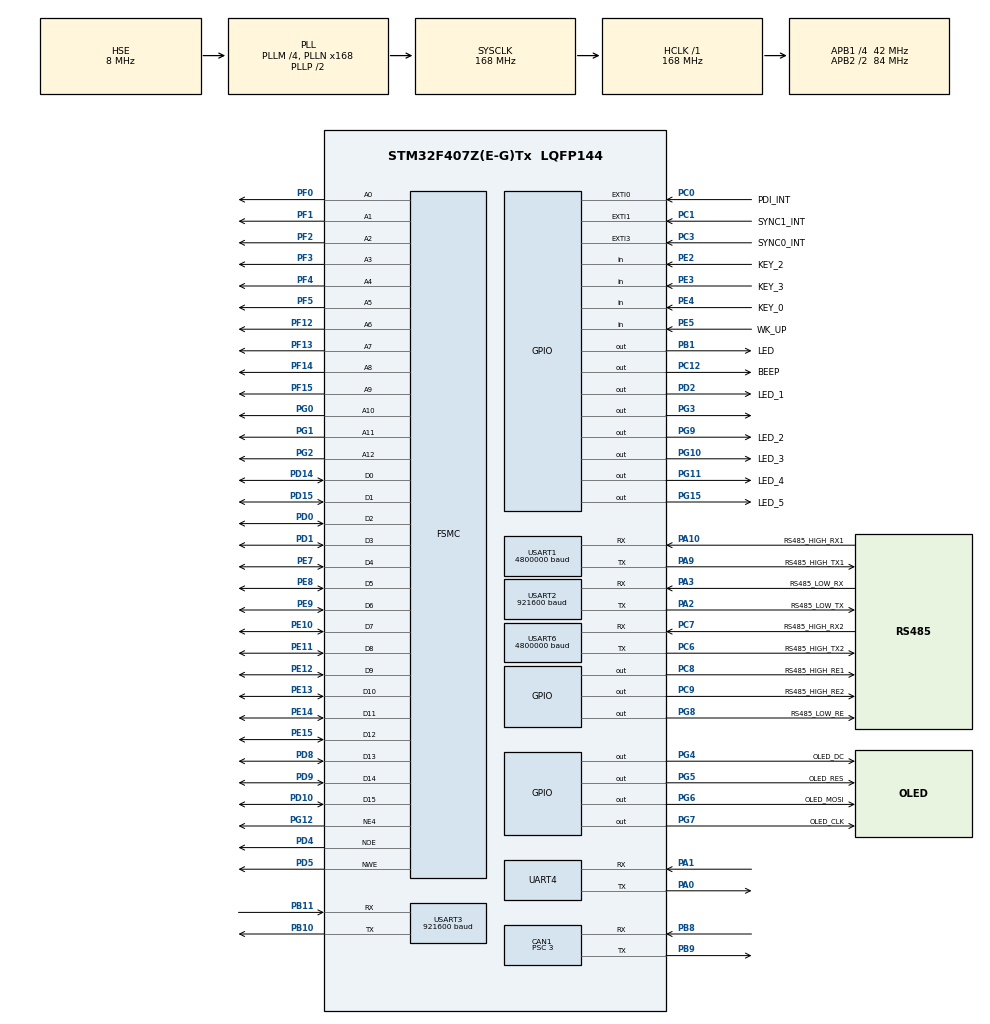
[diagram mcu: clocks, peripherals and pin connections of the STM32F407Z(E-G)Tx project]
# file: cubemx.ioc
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CAN1.BS1=CAN_BS1_9TQ
CAN1.BS2=CAN_BS2_4TQ
CAN1.CalculateBaudRate=1000000
CAN1.CalculateTimeBit=1000
CAN1.CalculateTimeQuantum=71.42857142857143
CAN1.Prescaler=3
Dma.Request0=USART1_RX
Dma.Request1=USART6_RX
Dma.Request2=USART1_TX
Dma.Request3=USART6_TX
Dma.USART1_RX.0.Direction=DMA_PERIPH_TO_MEMORY
Dma.USART1_RX.0.FIFOMode=DMA_FIFOMODE_DISABLE
Dma.USART1_RX.0.Instance=DMA2_Stream5
Dma.USART1_RX.0.MemDataAlignment=DMA_MDATAALIGN_BYTE
Dma.USART1_RX.0.MemInc=DMA_MINC_ENABLE
Dma.USART1_RX.0.Mode=DMA_NORMAL
Dma.USART1_RX.0.PeriphDataAlignment=DMA_PDATAALIGN_BYTE
Dma.USART1_RX.0.PeriphInc=DMA_PINC_DISABLE
Dma.USART1_RX.0.Priority=DMA_PRIORITY_VERY_HIGH
Dma.USART1_TX.2.Direction=DMA_MEMORY_TO_PERIPH
Dma.USART1_TX.2.FIFOMode=DMA_FIFOMODE_DISABLE
Dma.USART1_TX.2.Instance=DMA2_Stream7
Dma.USART1_TX.2.MemDataAlignment=DMA_MDATAALIGN_BYTE
Dma.USART1_TX.2.MemInc=DMA_MINC_ENABLE
Dma.USART1_TX.2.Mode=DMA_NORMAL
Dma.USART1_TX.2.PeriphDataAlignment=DMA_PDATAALIGN_BYTE
Dma.USART1_TX.2.PeriphInc=DMA_PINC_DISABLE
Dma.USART1_TX.2.Priority=DMA_PRIORITY_VERY_HIGH
Dma.USART6_RX.1.Direction=DMA_PERIPH_TO_MEMORY
Dma.USART6_RX.1.FIFOMode=DMA_FIFOMODE_DISABLE
Dma.USART6_RX.1.Instance=DMA2_Stream2
Dma.USART6_RX.1.MemDataAlignment=DMA_MDATAALIGN_BYTE
Dma.USART6_RX.1.MemInc=DMA_MINC_ENABLE
Dma.USART6_RX.1.Mode=DMA_NORMAL
Dma.USART6_RX.1.PeriphDataAlignment=DMA_PDATAALIGN_BYTE
Dma.USART6_RX.1.PeriphInc=DMA_PINC_DISABLE
Dma.USART6_RX.1.Priority=DMA_PRIORITY_VERY_HIGH
Dma.USART6_TX.3.Direction=DMA_MEMORY_TO_PERIPH
Dma.USART6_TX.3.FIFOMode=DMA_FIFOMODE_DISABLE
Dma.USART6_TX.3.Instance=DMA2_Stream6
Dma.USART6_TX.3.MemDataAlignment=DMA_MDATAALIGN_BYTE
Dma.USART6_TX.3.MemInc=DMA_MINC_ENABLE
Dma.USART6_TX.3.Mode=DMA_NORMAL
Dma.USART6_TX.3.PeriphDataAlignment=DMA_PDATAALIGN_BYTE
Dma.USART6_TX.3.PeriphInc=DMA_PINC_DISABLE
Dma.USART6_TX.3.Priority=DMA_PRIORITY_VERY_HIGH
FSMC.AddressSetupTime1=1
FSMC.BusTurnAroundDuration1=2
FSMC.DataSetupTime1=95
FSMC.WriteOperation1=FSMC_WRITE_OPERATION_ENABLE
Mcu.Family=STM32F4
Mcu.Name=STM32F407Z(E-G)Tx
Mcu.Package=LQFP144
NVIC.CAN1_RX0_IRQn=true\:0\:0\:false\:false\:true\:true\:true\:true
NVIC.CAN1_RX1_IRQn=true\:0\:0\:false\:false\:true\:true\:true\:true
NVIC.DMA2_Stream2_IRQn=true\:0\:0\:false\:false\:true\:true\:true\:true
NVIC.DMA2_Stream5_IRQn=true\:0\:0\:false\:false\:true\:false\:true\:true
NVIC.DMA2_Stream6_IRQn=true\:0\:0\:false\:false\:true\:false\:true\:true
NVIC.DMA2_Stream7_IRQn=true\:0\:0\:false\:false\:true\:false\:true\:true
NVIC.EXTI0_IRQn=true\:0\:0\:false\:false\:true\:true\:true\:true
NVIC.EXTI1_IRQn=true\:0\:0\:false\:false\:true\:true\:true\:true
NVIC.EXTI3_IRQn=true\:0\:0\:false\:false\:true\:true\:true\:true
NVIC.PriorityGroup=NVIC_PRIORITYGROUP_4
NVIC.TIM2_IRQn=true\:0\:0\:true\:false\:true\:true\:true\:true
NVIC.TIM3_IRQn=true\:5\:0\:true\:false\:true\:true\:true\:true
NVIC.TIM4_IRQn=true\:1\:0\:true\:false\:true\:true\:true\:true
NVIC.TIM5_IRQn=true\:0\:0\:true\:false\:true\:true\:true\:true
NVIC.UART4_IRQn=true\:0\:0\:false\:false\:true\:true\:true\:true
NVIC.USART1_IRQn=true\:0\:0\:false\:false\:true\:true\:true\:true
NVIC.USART2_IRQn=true\:0\:0\:false\:false\:true\:true\:true\:true
NVIC.USART3_IRQn=true\:0\:0\:false\:false\:true\:true\:true\:true
NVIC.USART6_IRQn=true\:0\:0\:false\:false\:true\:true\:true\:true
PA0-WKUP.Mode=Asynchronous
PA0-WKUP.Signal=UART4_TX
PA1.Mode=Asynchronous
PA1.Signal=UART4_RX
PA10.GPIO_Label=RS485_HIGH_RX1
PA10.Mode=Asynchronous
PA10.Signal=USART1_RX
PA13.Mode=Serial_Wire
PA13.Signal=SYS_JTMS-SWDIO
PA14.Mode=Serial_Wire
PA14.Signal=SYS_JTCK-SWCLK
PA2.GPIO_Label=RS485_LOW_TX
PA2.Mode=Asynchronous
PA2.Signal=USART2_TX
PA3.GPIO_Label=RS485_LOW_RX
PA3.Mode=Asynchronous
PA3.Signal=USART2_RX
PA9.GPIO_Label=RS485_HIGH_TX1
PA9.Mode=Asynchronous
PA9.Signal=USART1_TX
PB1.GPIO_Label=LED
PB1.Signal=GPIO_Output
PB10.Mode=Asynchronous
PB10.Signal=USART3_TX
PB11.Mode=Asynchronous
PB11.Signal=USART3_RX
PB8.Mode=CAN_Activate
PB8.Signal=CAN1_RX
PB9.Mode=CAN_Activate
PB9.Signal=CAN1_TX
PC0.GPIO_Label=PDI_INT
PC0.GPIO_ModeDefaultEXTI=GPIO_MODE_IT_FALLING
PC0.GPIO_PuPd=GPIO_PULLUP
PC0.Signal=GPXTI0
PC1.GPIO_Label=SYNC1_INT
PC1.GPIO_ModeDefaultEXTI=GPIO_MODE_IT_FALLING
PC1.GPIO_PuPd=GPIO_PULLUP
PC1.Signal=GPXTI1
PC12.GPIO_Label=BEEP
PC12.GPIO_PuPd=GPIO_PULLDOWN
PC12.GPIO_Speed=GPIO_SPEED_FREQ_HIGH
PC12.Signal=GPIO_Output
PC3.GPIO_Label=SYNC0_INT
PC3.GPIO_ModeDefaultEXTI=GPIO_MODE_IT_FALLING
PC3.GPIO_PuPd=GPIO_PULLUP
PC3.Signal=GPXTI3
PC6.GPIO_Label=RS485_HIGH_TX2
PC6.Mode=Asynchronous
PC6.Signal=USART6_TX
PC7.GPIO_Label=RS485_HIGH_RX2
PC7.Mode=Asynchronous
PC7.Signal=USART6_RX
PC8.GPIO_Label=RS485_HIGH_RE1
PC8.GPIO_PuPd=GPIO_PULLUP
PC8.GPIO_Speed=GPIO_SPEED_FREQ_HIGH
PC8.Signal=GPIO_Output
PC9.GPIO_Label=RS485_HIGH_RE2
PC9.GPIO_PuPd=GPIO_PULLUP
PC9.GPIO_Speed=GPIO_SPEED_FREQ_HIGH
PC9.Signal=GPIO_Output
PD0.Signal=FSMC_D2_DA2
PD1.Signal=FSMC_D3_DA3
PD10.Signal=FSMC_D15_DA15
PD14.Signal=FSMC_D0_DA0
PD15.Signal=FSMC_D1_DA1
PD2.GPIO_Label=LED_1
PD2.Signal=GPIO_Output
PD4.Signal=FSMC_NOE
PD5.Signal=FSMC_NWE
PD8.Signal=FSMC_D13_DA13
PD9.Signal=FSMC_D14_DA14
PE10.Signal=FSMC_D7_DA7
PE11.Signal=FSMC_D8_DA8
PE12.Signal=FSMC_D9_DA9
PE13.Signal=FSMC_D10_DA10
PE14.Signal=FSMC_D11_DA11
PE15.Signal=FSMC_D12_DA12
PE2.GPIO_Label=KEY_2
PE2.GPIO_PuPd=GPIO_PULLUP
PE2.Signal=GPIO_Input
PE3.GPIO_Label=KEY_3
PE3.GPIO_PuPd=GPIO_PULLUP
PE3.Signal=GPIO_Input
PE4.GPIO_Label=KEY_0
PE4.GPIO_PuPd=GPIO_PULLUP
PE4.Signal=GPIO_Input
PE5.GPIO_Label=WK_UP
PE5.GPIO_PuPd=GPIO_PULLUP
PE5.Signal=GPIO_Input
PE7.Signal=FSMC_D4_DA4
PE8.Signal=FSMC_D5_DA5
PE9.Signal=FSMC_D6_DA6
PF0.Signal=FSMC_A0
PF1.Signal=FSMC_A1
PF12.Signal=FSMC_A6
PF13.Signal=FSMC_A7
PF14.Signal=FSMC_A8
PF15.Signal=FSMC_A9
PF2.Signal=FSMC_A2
PF3.Signal=FSMC_A3
PF4.Signal=FSMC_A4
PF5.Signal=FSMC_A5
PG0.Signal=FSMC_A10
PG1.Signal=FSMC_A11
PG10.GPIO_Label=LED_3
PG10.Signal=GPIO_Output
PG11.GPIO_Label=LED_4
PG11.Signal=GPIO_Output
PG12.Mode=NorPsramChipSelect4_1
PG12.Signal=FSMC_NE4
PG15.GPIO_Label=LED_5
PG15.Signal=GPIO_Output
PG2.Signal=FSMC_A12
PG3.Signal=GPIO_Output
PG4.GPIO_Label=OLED_DC
PG4.GPIO_PuPd=GPIO_PULLUP
PG4.GPIO_Speed=GPIO_SPEED_FREQ_HIGH
PG4.Signal=GPIO_Output
PG5.GPIO_Label=OLED_RES
PG5.GPIO_PuPd=GPIO_PULLUP
PG5.GPIO_Speed=GPIO_SPEED_FREQ_HIGH
PG5.Signal=GPIO_Output
PG6.GPIO_Label=OLED_MOSI
PG6.GPIO_PuPd=GPIO_PULLUP
PG6.GPIO_Speed=GPIO_SPEED_FREQ_HIGH
PG6.Signal=GPIO_Output
PG7.GPIO_Label=OLED_CLK
PG7.GPIO_PuPd=GPIO_PULLUP
PG7.GPIO_Speed=GPIO_SPEED_FREQ_HIGH
PG7.Signal=GPIO_Output
PG8.GPIO_Label=RS485_LOW_RE
PG8.GPIO_PuPd=GPIO_PULLUP
PG8.GPIO_Speed=GPIO_SPEED_FREQ_HIGH
PG8.Signal=GPIO_Output
PG9.GPIO_Label=LED_2
PG9.GPIO_ModeDefaultOutputPP=GPIO_MODE_OUTPUT_PP
PG9.Signal=GPIO_Output
PH0-OSC_IN.Mode=HSE-External-Oscillator
PH0-OSC_IN.Signal=RCC_OSC_IN
PH1-OSC_OUT.Mode=HSE-External-Oscillator
PH1-OSC_OUT.Signal=RCC_OSC_OUT
ProjectManager.HeapSize=0x2000
ProjectManager.StackSize=0x4000
ProjectManager.TargetToolchain=MDK-ARM V5.32
RCC.48MHZClocksFreq_Value=84000000
RCC.AHBFreq_Value=168000000
RCC.APB1CLKDivider=RCC_HCLK_DIV4
RCC.APB1Freq_Value=42000000
RCC.APB1TimFreq_Value=84000000
RCC.APB2CLKDivider=RCC_HCLK_DIV2
RCC.APB2Freq_Value=84000000
RCC.APB2TimFreq_Value=168000000
RCC.CortexFreq_Value=168000000
RCC.HCLKFreq_Value=168000000
RCC.HSE_VALUE=8000000
RCC.HSI_VALUE=16000000
RCC.LSE_VALUE=32768
RCC.PLLM=4
RCC.PLLN=168
RCC.PLLSourceVirtual=RCC_PLLSOURCE_HSE
RCC.SYSCLKFreq_VALUE=168000000
RCC.SYSCLKSource=RCC_SYSCLKSOURCE_PLLCLK
RCC.VCOOutputFreq_Value=336000000
SH.FSMC_A0.0=FSMC_A0,13b-a1
SH.FSMC_A1.0=FSMC_A1,13b-a1
SH.FSMC_A10.0=FSMC_A10,13b-a1
SH.FSMC_A11.0=FSMC_A11,13b-a1
SH.FSMC_A12.0=FSMC_A12,13b-a1
SH.FSMC_A2.0=FSMC_A2,13b-a1
SH.FSMC_A3.0=FSMC_A3,13b-a1
SH.FSMC_A4.0=FSMC_A4,13b-a1
SH.FSMC_A5.0=FSMC_A5,13b-a1
SH.FSMC_A6.0=FSMC_A6,13b-a1
SH.FSMC_A7.0=FSMC_A7,13b-a1
SH.FSMC_A8.0=FSMC_A8,13b-a1
SH.FSMC_A9.0=FSMC_A9,13b-a1
SH.FSMC_D0_DA0.0=FSMC_D0,16b-d1
SH.FSMC_D10_DA10.0=FSMC_D10,16b-d1
SH.FSMC_D11_DA11.0=FSMC_D11,16b-d1
SH.FSMC_D12_DA12.0=FSMC_D12,16b-d1
SH.FSMC_D13_DA13.0=FSMC_D13,16b-d1
SH.FSMC_D14_DA14.0=FSMC_D14,16b-d1
SH.FSMC_D15_DA15.0=FSMC_D15,16b-d1
SH.FSMC_D1_DA1.0=FSMC_D1,16b-d1
SH.FSMC_D2_DA2.0=FSMC_D2,16b-d1
SH.FSMC_D3_DA3.0=FSMC_D3,16b-d1
SH.FSMC_D4_DA4.0=FSMC_D4,16b-d1
SH.FSMC_D5_DA5.0=FSMC_D5,16b-d1
SH.FSMC_D6_DA6.0=FSMC_D6,16b-d1
SH.FSMC_D7_DA7.0=FSMC_D7,16b-d1
SH.FSMC_D8_DA8.0=FSMC_D8,16b-d1
SH.FSMC_D9_DA9.0=FSMC_D9,16b-d1
SH.FSMC_NOE.0=FSMC_NOE,Sram1
SH.FSMC_NWE.0=FSMC_NWE,Sram1
TIM2.AutoReloadPreload=TIM_AUTORELOAD_PRELOAD_ENABLE
TIM2.Period=3999
TIM2.Prescaler=3
TIM3.AutoReloadPreload=TIM_AUTORELOAD_PRELOAD_ENABLE
TIM3.Period=1000
TIM3.Prescaler=83
TIM4.AutoReloadPreload=TIM_AUTORELOAD_PRELOAD_ENABLE
TIM4.Period=3999
TIM4.Prescaler=2099
TIM5.AutoReloadPreload=TIM_AUTORELOAD_PRELOAD_ENABLE
TIM5.Period=3999
TIM5.Prescaler=10
UART4.VirtualMode=Asynchronous
USART1.BaudRate=4800000
USART1.VirtualMode=VM_ASYNC
USART2.BaudRate=921600
USART2.VirtualMode=VM_ASYNC
USART3.BaudRate=921600
USART3.VirtualMode=VM_ASYNC
USART6.BaudRate=4800000
USART6.VirtualMode=VM_ASYNC
VP_CRC_VS_CRC.Mode=CRC_Activate
VP_TIM2_VS_ClockSourceINT.Mode=Internal
VP_TIM3_VS_ClockSourceINT.Mode=Internal
VP_TIM4_VS_ClockSourceINT.Mode=Internal
VP_TIM5_VS_ClockSourceINT.Mode=Internal
board=custom

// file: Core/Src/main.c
/* USER CODE BEGIN Header */
/**
  ******************************************************************************
  * @file           : main.c
  * @brief          : Main program body
  ******************************************************************************
  * @attention
  *
  * Copyright (c) 2024 STMicroelectronics.
  * All rights reserved.
  *
  * This software is licensed under terms that can be found in the LICENSE file
  * in the root directory of this software component.
  * If no LICENSE file comes with this software, it is provided AS-IS.
  *
  ******************************************************************************
  */
/* USER CODE END Header */
#include "main.h"
#include "can.h"
#include "crc.h"
#include "dma.h"
#include "tim.h"
#include "usart.h"
#include "gpio.h"
#include "fsmc.h"

/* USER CODE BEGIN Includes */
#include "ecat_def.h"
#include "applInterface.h"
#include "SSC-Device.h"
#include "oled.h"
#include "stdio.h"
#include "cpp_app.h"
#include "bsp_can.h"

/* USER CODE END Includes */

/* USER CODE BEGIN PTD */
/* 告知连接器不从C库链接使用半主机的函数 */

//#pragma import(__use_no_semihosting)

/* 定义 _sys_exit() 以避免使用半主机模式 */

void _sys_exit(int x)

{

    x = x;

}

/* USER CODE END PTD */

/* USER CODE BEGIN PV */

int8_t flag;

extern float hz_detect ;

/* USER CODE END PV */

void SystemClock_Config(void);

/* USER CODE BEGIN 0 */
void OLED_ShowStatus()
{
    // 显示 D1 D2 D3 D4 对应 M8 的状态
    for (int i = 6; i < 10; i++)  // M8 对应 CheckList 中的 M8_MOTOR1_TOE, M8_MOTOR2_TOE, M8_MOTOR3_TOE, M8_MOTOR4_TOE
    {
        uint8_t status_char = '1';  // 默认正常状态，显示'1'（正常）

        if (error_list[i].error_exist)
        {
            if (error_list[i].is_lost)
            {
                status_char = '0';  // 错误且丢失，显示'0'（丢失）
            }
            else
            {
                status_char = '0';  // 仅错误，显示'2'（错误）
            }
        }
        else if (error_list[i].is_lost)
        {
            status_char = '0';  // 仅丢失，显示'0'（丢失）
        }

        // 计算显示位置（D1 D2 D3 D4 显示在第二行）
        int row = 0;  // 频率显示的上方，即第二行
        int col = (i - 6) * 30;  // D1 D2 D3 D4 显示间隔为36像素

        // 显示 D1, D2, D3, D4 和状态
        OLED_ShowChar(col, row, 'D', 12, 1);  // 显示'D'
        OLED_ShowChar(col + 8, row, '1' + (i - 6), 12, 1);  // 显示 D1, D2, D3, D4
        OLED_ShowChar(col + 16, row, ':', 12, 1);  // 显示冒号
        OLED_ShowChar(col + 24, row, status_char, 12, 1);  // 显示状态 '0', '1' 或 '2'
    }

    // 显示设备状态 (原来的设备状态从第三行开始)
    for (int i = 0; i < 6; i++)  // 前6个设备
    {
        uint8_t status_char = '1';  // 默认正常状态，显示'1'（正常）

        if (error_list[i].error_exist)
        {
            if (error_list[i].is_lost)
            {
                status_char = '0';  // 错误且丢失，显示'0'（丢失）
            }
            else
            {
                status_char = '0';  // 仅错误，显示'2'（错误）
            }
        }
        else if (error_list[i].is_lost)
        {
            status_char = '0';  // 仅丢失，显示'0'（丢失）
        }

        // 计算显示位置（M1, M2, M3, M4, M5, M6 从第三行开始显示）
        int row = 16 + (i / 3) * 16;  // 每行显示三个设备
        int col = (i % 3) * 36;  // 每个设备占36个像素位置，调整列间距

        // 显示 M1, M2, M3, ... 和状态
        OLED_ShowChar(col, row, 'M', 12, 1);  // 显示'M'
        OLED_ShowChar(col + 8, row, '1' + i, 12, 1);  // 显示M1, M2, M3, ...
        OLED_ShowChar(col + 16, row, ':', 12, 1);  // 显示冒号
        OLED_ShowChar(col + 24, row, status_char, 12, 1);  // 显示状态 '0', '1' 或 '2'
    }

    // 显示控制频率
    char freq_str[16];
    snprintf(freq_str, sizeof(freq_str), "Freq: %.2f Hz", hz_detect);  // 格式化频率字符串
    OLED_ShowString(0, 48, freq_str, 12);  // 在最后一行显示控制频率，向上平移

    // 刷新OLED显示
    OLED_Refresh_Gram();
}

/* USER CODE END 0 */

int main(void)
{

  /* MCU Configuration--------------------------------------------------------*/

  /* Reset of all peripherals, Initializes the Flash interface and the Systick. */
  HAL_Init();

  /* Configure the system clock */
  SystemClock_Config();

  /* Initialize all configured peripherals */
  MX_GPIO_Init();
  MX_DMA_Init();
  MX_FSMC_Init();
  MX_TIM3_Init();
  MX_UART4_Init();
  MX_USART1_UART_Init();
  MX_USART2_UART_Init();
  MX_USART3_UART_Init();
  MX_USART6_UART_Init();
  MX_CAN1_Init();
  MX_CRC_Init();
  MX_TIM2_Init();
  MX_TIM4_Init();
  MX_TIM5_Init();
  /* USER CODE BEGIN 2 */
	HW_Init();
	MainInit();

	can_filter_init(&hcan1);

	cpp_main_init();

	HAL_TIM_Base_Start_IT(&htim2);
	HAL_TIM_Base_Start_IT(&htim4);
	HAL_TIM_Base_Start_IT(&htim5);

	OLED_Init();
	//OLED_ShowString(0,0,"SONY-EtherCAT ",16);
	//OLED_ShowString(0,16, "Servo Drive",12);
	//OLED_ShowString(0,28,"AX58100+F407",12);
	//OLED_ShowString(0,45,"TIME 2025/2/17",12);
	//OLED_Refresh_Gram();//������ʾ��OLED
		bRunApplication = TRUE;
	do
	{

		OLED_ShowStatus();
		//HAL_Delay(100);

		HAL_GPIO_TogglePin(GPIOG, LED_2_Pin);
		MainLoop();
	} while (bRunApplication == TRUE);
	HW_Release();
  /* USER CODE END 2 */

  /* Infinite loop */
  while (1)
  {

  }
}

void SystemClock_Config(void)
{
  RCC_OscInitTypeDef RCC_OscInitStruct = {0};
  RCC_ClkInitTypeDef RCC_ClkInitStruct = {0};

  /** Configure the main internal regulator output voltage
  */
  __HAL_RCC_PWR_CLK_ENABLE();
  __HAL_PWR_VOLTAGESCALING_CONFIG(PWR_REGULATOR_VOLTAGE_SCALE1);

  /** Initializes the RCC Oscillators according to the specified parameters
  * in the RCC_OscInitTypeDef structure.
  */
  RCC_OscInitStruct.OscillatorType = RCC_OSCILLATORTYPE_HSE;
  RCC_OscInitStruct.HSEState = RCC_HSE_ON;
  RCC_OscInitStruct.PLL.PLLState = RCC_PLL_ON;
  RCC_OscInitStruct.PLL.PLLSource = RCC_PLLSOURCE_HSE;
  RCC_OscInitStruct.PLL.PLLM = 4;
  RCC_OscInitStruct.PLL.PLLN = 168;
  RCC_OscInitStruct.PLL.PLLP = RCC_PLLP_DIV2;
  RCC_OscInitStruct.PLL.PLLQ = 4;
  if (HAL_RCC_OscConfig(&RCC_OscInitStruct) != HAL_OK)
  {
    Error_Handler();
  }

  /** Initializes the CPU, AHB and APB buses clocks
  */
  RCC_ClkInitStruct.ClockType = RCC_CLOCKTYPE_HCLK|RCC_CLOCKTYPE_SYSCLK
                              |RCC_CLOCKTYPE_PCLK1|RCC_CLOCKTYPE_PCLK2;
  RCC_ClkInitStruct.SYSCLKSource = RCC_SYSCLKSOURCE_PLLCLK;
  RCC_ClkInitStruct.AHBCLKDivider = RCC_SYSCLK_DIV1;
  RCC_ClkInitStruct.APB1CLKDivider = RCC_HCLK_DIV4;
  RCC_ClkInitStruct.APB2CLKDivider = RCC_HCLK_DIV2;

  if (HAL_RCC_ClockConfig(&RCC_ClkInitStruct, FLASH_LATENCY_5) != HAL_OK)
  {
    Error_Handler();
  }
}

/* USER CODE BEGIN 4 */

/************* EXTI TEST ************/
//void HAL_GPIO_EXTI_Callback(uint16_t GPIO_Pin)
//{
//	if(GPIO_Pin==PDI_INT_Pin)
//	{
//		SEGGER_RTT_printf(0, "PDI_INT_Pin\n");
//	}
//	else if(GPIO_Pin==SYNC0_INT_Pin)
//	{
//		SEGGER_RTT_printf(0, "SYNC0_INT_Pin\n");
//	}
//	else if(GPIO_Pin==SYNC1_INT_Pin)
//	{
//		SEGGER_RTT_printf(0, "SYNC1_INT_Pin\n");
//	}
//}

/************* TIMER TEST ************/
//void HAL_TIM_PeriodElapsedCallback(TIM_HandleTypeDef *htim)
//{
//	if(htim == &htim3)
//	{
//		ECAT_CheckTimer();
//		static uint16_t i = 0;
//		i++;
//		if(i == 1000)
//		{
//			SEGGER_RTT_printf(0, "HAL_TIM_PeriodElapsedCallback\n");
//			i = 0;
//		}
//	}
//}

/************* FSMC test ************/
//		if(HAL_GPIO_ReadPin(KEY_GPIO_Port, KEY_Pin) == GPIO_PIN_RESET)
//		{
//				for(uint8_t i = 0; i < 128; i++)
//				{
//						for(uint8_t j = 0; j < 64; j++)
//						{
//							 SEGGER_RTT_printf(0, "%02x ", *((uint8_t *)(0x6C000000) + j + i*128));
//						}
//						SEGGER_RTT_printf(0, "\n");
//						HAL_Delay(2);
//				}
//		}
//		HAL_Delay(2000);

/* USER CODE END 4 */

void Error_Handler(void)
{
  __disable_irq();
  while (1)
  {
  }
}
